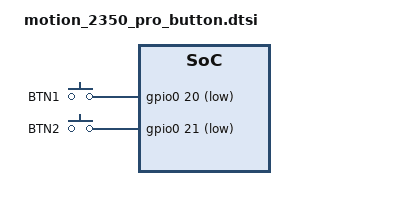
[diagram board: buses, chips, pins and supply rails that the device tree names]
/*
 * Copyright (c) 2026 TiaC Systems
 * SPDX-License-Identifier: Apache-2.0
 */

#include <zephyr/dt-bindings/input/input-event-codes.h>
#include <zephyr/dt-bindings/lvgl/lvgl.h>
#include <zephyr/dt-bindings/gpio/gpio.h>

/ {
	aliases {
		sw0 = &btn0;
		sw1 = &btn1;
	};

	lvgl_keypad: lvgl-keypad {
		compatible = "zephyr,lvgl-keypad-input";
		input = <&gpio_keys>;
		input-codes = <INPUT_KEY_0 INPUT_KEY_1>;
		lvgl-codes = <LV_KEY_ENTER LV_KEY_NEXT>;
	};

	gpio_keys: gpio_keys {
		compatible = "gpio-keys";
		status = "okay";

		btn0: btn_0 {
			gpios = <&gpio0 20 GPIO_ACTIVE_LOW>;
			zephyr,code = <INPUT_KEY_0>;
			label = "BTN1";
		};
		btn1: btn_1 {
			gpios = <&gpio0 21 GPIO_ACTIVE_LOW>;
			zephyr,code = <INPUT_KEY_1>;
			label = "BTN2";
		};
	};
};

&gpio0 {
	status = "okay";
};
